# STM32U575 register map
File version: 1.3
CPU: CM33 r0p1, little endian, MPU, FPU, 4 interrupt priority bits
Registers are 32-bit, read-write, reset 0x0 unless marked. A register's access mark holds for its fields unless they carry their own. Offsets are from the block's base; [hi:lo] are bit positions; 'fields as' and 'values as' point back to an identical list.

## OCTOSPI1 — OctoSPI
Base 0x420D1400
Same registers: OCTOSPI2 0x420D2400, SEC_OCTOSPI1 0x520D1400, SEC_OCTOSPI2 0x520D2400
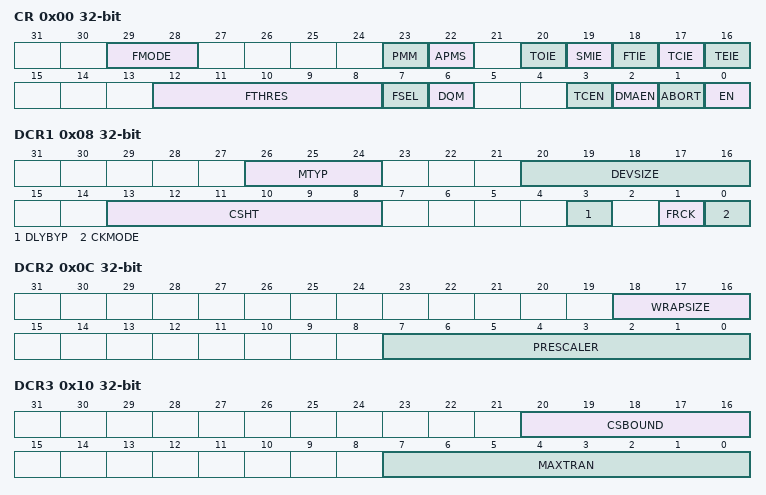
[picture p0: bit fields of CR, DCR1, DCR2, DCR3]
0x00 CR — control register
  [29:28] FMODE — Functional mode
  [23] PMM — Polling match mode
  [22] APMS — Automatic poll mode stop
  [20] TOIE — TimeOut interrupt enable
  [19] SMIE — Status match interrupt enable
  [18] FTIE — FIFO threshold interrupt enable
  [17] TCIE — Transfer complete interrupt enable
  [16] TEIE — Transfer error interrupt enable
  [12:8] FTHRES — IFO threshold level
  [7] FSEL — FLASH memory selection
  [6] DQM — Dual-quad mode
  [3] TCEN — Timeout counter enable
  [2] DMAEN — DMA enable
  [1] ABORT — Abort request
  [0] EN — Enable
0x08 DCR1 — device configuration register 1
  [26:24] MTYP — Memory type
  [20:16] DEVSIZE — Device size
  [13:8] CSHT — Chip-select high time
  [3] DLYBYP — Delay block bypass
  [1] FRCK — Free running clock
  [0] CKMODE — Mode 0 / mode 3
0x0C DCR2 — device configuration register 2
  [18:16] WRAPSIZE
  [7:0] PRESCALER — Clock prescaler
0x10 DCR3 — device configuration register 3
  [20:16] CSBOUND — CS boundary
  [7:0] MAXTRAN — Maximum transfer
0x14 DCR4
  [31:0] REFRESH — Refresh rate
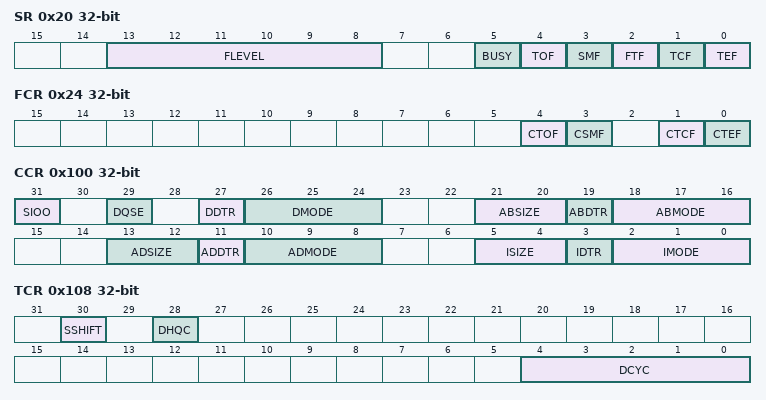
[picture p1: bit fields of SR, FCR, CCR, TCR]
0x20 SR ro — status register
  [13:8] FLEVEL — FIFO level
  [5] BUSY
  [4] TOF — timeout flag
  [3] SMF — status match flag
  [2] FTF — FIFO threshold flag
  [1] TCF — transfer complete flag
  [0] TEF — Transfer error flag
0x24 FCR wo — flag clear register
  [4] CTOF — Clear timeout flag
  [3] CSMF — Clear status match flag
  [1] CTCF — Clear transfer complete flag
  [0] CTEF — Clear Transfer error flag
0x40 DLR — data length register
  [31:0] DL — Data length
0x48 AR — address register
  [31:0] ADDRESS
0x50 DR — data register
  [31:0] DATA
0x80 PSMKR — polling status mask register
  [31:0] MASK — Status MASK
0x88 PSMAR — polling status match register
  [31:0] MATCH — Status match
0x90 PIR — polling interval register
  [15:0] INTERVAL — polling interval
0x100 CCR — communication configuration register
  [31] SIOO — Send instruction only once mode
  [29] DQSE — DQS enable
  [27] DDTR — Alternate bytes double transfer rate
  [26:24] DMODE — Data mode
  [21:20] ABSIZE — Alternate bytes size
  [19] ABDTR — Alternate bytes double transfer rate
  [18:16] ABMODE — Alternate byte mode
  [13:12] ADSIZE — Address size
  [11] ADDTR — Address double transfer rate
  [10:8] ADMODE — Address mode
  [5:4] ISIZE — Instruction size
  [3] IDTR — Instruction double transfer rate
  [2:0] IMODE — Instruction mode
0x108 TCR — timing configuration register
  [30] SSHIFT — Sample shift
  [28] DHQC — Delay hold quarter cycle
  [4:0] DCYC — Number of dummy cycles
0x110 IR — instruction register
  [31:0] INSTRUCTION
0x120 ABR — alternate bytes register
  [31:0] ALTERNATE — Alternate bytes
0x130 LPTR — low-power timeout register
  [15:0] TIMEOUT — Timeout period
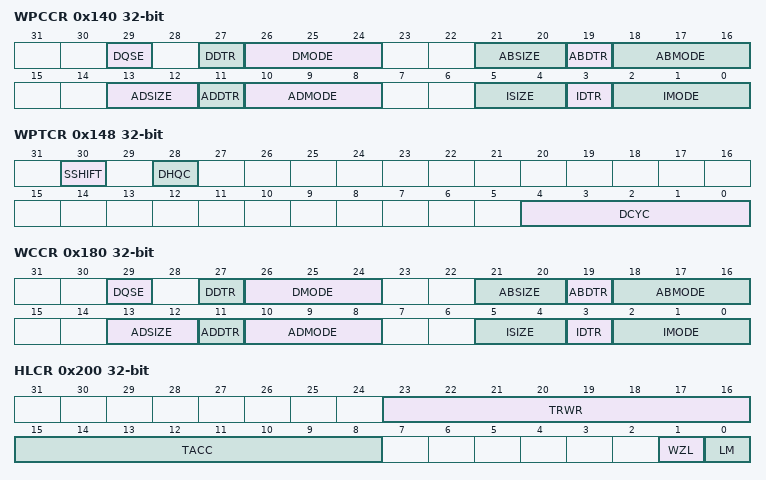
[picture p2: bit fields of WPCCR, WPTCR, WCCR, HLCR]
0x140 WPCCR — wrap communication configuration register
  [29] DQSE — DQS enable
  [27] DDTR — alternate bytes double transfer rate
  [26:24] DMODE — Data mode
  [21:20] ABSIZE — Alternate bytes size
  [19] ABDTR — Alternate bytes double transfer rate
  [18:16] ABMODE — Alternate byte mode
  [13:12] ADSIZE — Address size
  [11] ADDTR — Address double transfer rate
  [10:8] ADMODE — Address mode
  [5:4] ISIZE — Instruction size
  [3] IDTR — Instruction double transfer rate
  [2:0] IMODE — Instruction mode
0x148 WPTCR — wrap timing configuration register
  fields as TCR
0x150 WPIR — wrap instruction register
  [31:0] INSTRUCTION
0x160 WPABR — wrap alternate bytes register
  [31:0] ALTERNATE — Alternate bytes
0x180 WCCR — write communication configuration register
  fields as WPCCR
0x188 WTCR — write timing configuration register
  [4:0] DCYC — Number of dummy cycles
0x190 WIR — write instruction register
  [31:0] INSTRUCTION
0x1A0 WABR — write alternate bytes register
  [31:0] ALTERNATE
0x200 HLCR — HyperBus latency configuration register
  [23:16] TRWR — Read write recovery time
  [15:8] TACC — Access time
  [1] WZL — Write zero latency
  [0] LM — Latency mode
